VERSION ""

NS_ :

BS_:

BU_: BMS VCU

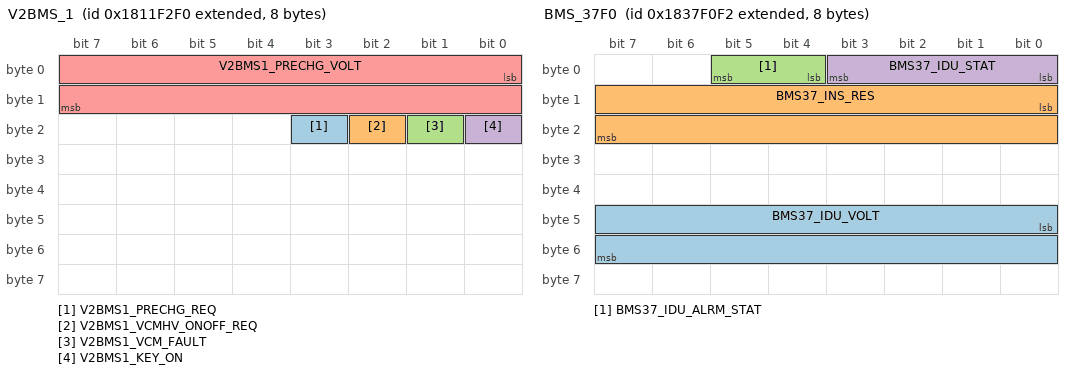
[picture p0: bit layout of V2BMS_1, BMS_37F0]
BO_ 2551313136 V2BMS_1: 8 VCU
 SG_ V2BMS1_PRECHG_REQ : 19|1@1+ (1,0) [0|0] "" BMS
 SG_ V2BMS1_VCMHV_ONOFF_REQ : 18|1@1+ (1,0) [0|0] "" BMS
 SG_ V2BMS1_VCM_FAULT : 17|1@1+ (1,0) [0|0] "" BMS
 SG_ V2BMS1_KEY_ON : 16|1@1+ (1,0) [0|0] "" BMS
 SG_ V2BMS1_PRECHG_VOLT : 0|16@1+ (0.02,0) [0|1310.7] "V" BMS

BO_ 2553802994 BMS_37F0: 8 BMS
 SG_ BMS37_IDU_VOLT : 40|16@1+ (0.02,0) [0|1310.7] "V" VCU
 SG_ BMS37_INS_RES : 8|16@1+ (1,0) [0|65534] "KΩ" VCU
 SG_ BMS37_IDU_ALRM_STAT : 4|2@1+ (1,0) [0|3] "" VCU
 SG_ BMS37_IDU_STAT : 0|4@1+ (1,0) [0|15] "" VCU
CM_ BU_ BMS "电池管理系统";
CM_ BU_ VCU "整车控制器";
BA_DEF_  "BusType" STRING ;
BA_DEF_ BO_ "GenMsgCycleTime" INT 0 65535;
BA_DEF_DEF_  "BusType" "CAN";
BA_ "GenMsgCycleTime" BO_ 2551313136 100 ;
BA_ "GenMsgCycleTime" BO_ 2553802994 200 ;
